# Espressif register map
File version: 1.0
CPU: Xtensa LX6 1, little endian, no MPU, FPU, 3 interrupt priority bits
Registers are 32-bit, access not given, reset 0x0 unless marked. A register's access mark holds for its fields unless they carry their own. Offsets are from the block's base; [hi:lo] are bit positions; {n}, {i} and the like mark numbered series.

## DPORT
Base 0x3FF00000
0x00 DPORT_PRO_BOOT_REMAP_CTRL
  [0] DPORT_PRO_BOOT_REMAP
0x04 DPORT_APP_BOOT_REMAP_CTRL
  [0] DPORT_APP_BOOT_REMAP
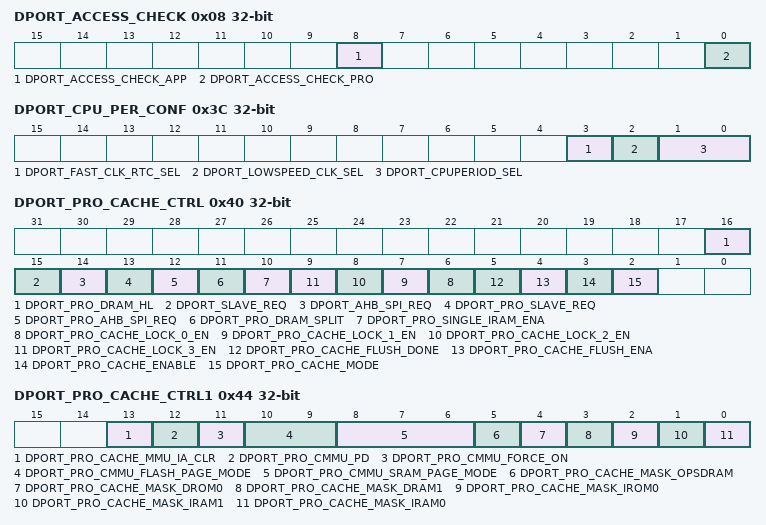
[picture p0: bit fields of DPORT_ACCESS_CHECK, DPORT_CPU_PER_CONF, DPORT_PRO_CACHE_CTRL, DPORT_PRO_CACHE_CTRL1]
0x08 DPORT_ACCESS_CHECK
  [8] DPORT_ACCESS_CHECK_APP, [0] DPORT_ACCESS_CHECK_PRO
0x0C DPORT_PRO_DPORT_APB_MASK0
  [31:0] DPORT_PRODPORT_APB_MASK0
0x10 DPORT_PRO_DPORT_APB_MASK1
  [31:0] DPORT_PRODPORT_APB_MASK1
0x14 DPORT_APP_DPORT_APB_MASK0
  [31:0] DPORT_APPDPORT_APB_MASK0
0x18 DPORT_APP_DPORT_APB_MASK1
  [31:0] DPORT_APPDPORT_APB_MASK1
0x1C DPORT_PERI_CLK_EN
0x20 DPORT_PERI_RST_EN
0x24 DPORT_WIFI_BB_CFG
0x28 DPORT_WIFI_BB_CFG_2
0x2C DPORT_APPCPU_CTRL_A
  [0] DPORT_APPCPU_RESETTING
0x30 DPORT_APPCPU_CTRL_B
  [0] DPORT_APPCPU_CLKGATE_EN
0x34 DPORT_APPCPU_CTRL_C
  [0] DPORT_APPCPU_RUNSTALL
0x38 DPORT_APPCPU_CTRL_D
  [31:0] DPORT_APPCPU_BOOT_ADDR
0x3C DPORT_CPU_PER_CONF
  [3] DPORT_FAST_CLK_RTC_SEL, [2] DPORT_LOWSPEED_CLK_SEL, [1:0] DPORT_CPUPERIOD_SEL
0x40 DPORT_PRO_CACHE_CTRL
  [16] DPORT_PRO_DRAM_HL, [15] DPORT_SLAVE_REQ, [14] DPORT_AHB_SPI_REQ, [13] DPORT_PRO_SLAVE_REQ, [12] DPORT_PRO_AHB_SPI_REQ, [11] DPORT_PRO_DRAM_SPLIT, [10] DPORT_PRO_SINGLE_IRAM_ENA, [n+6] DPORT_PRO_CACHE_LOCK_{n}_EN (n=0..3), [5] DPORT_PRO_CACHE_FLUSH_DONE, [4] DPORT_PRO_CACHE_FLUSH_ENA, [3] DPORT_PRO_CACHE_ENABLE, [2] DPORT_PRO_CACHE_MODE
0x44 DPORT_PRO_CACHE_CTRL1
  [13] DPORT_PRO_CACHE_MMU_IA_CLR, [12] DPORT_PRO_CMMU_PD, [11] DPORT_PRO_CMMU_FORCE_ON, [10:9] DPORT_PRO_CMMU_FLASH_PAGE_MODE, [8:6] DPORT_PRO_CMMU_SRAM_PAGE_MODE, [5] DPORT_PRO_CACHE_MASK_OPSDRAM, [4] DPORT_PRO_CACHE_MASK_DROM0, [3] DPORT_PRO_CACHE_MASK_DRAM1, [2] DPORT_PRO_CACHE_MASK_IROM0, [1] DPORT_PRO_CACHE_MASK_IRAM1, [0] DPORT_PRO_CACHE_MASK_IRAM0
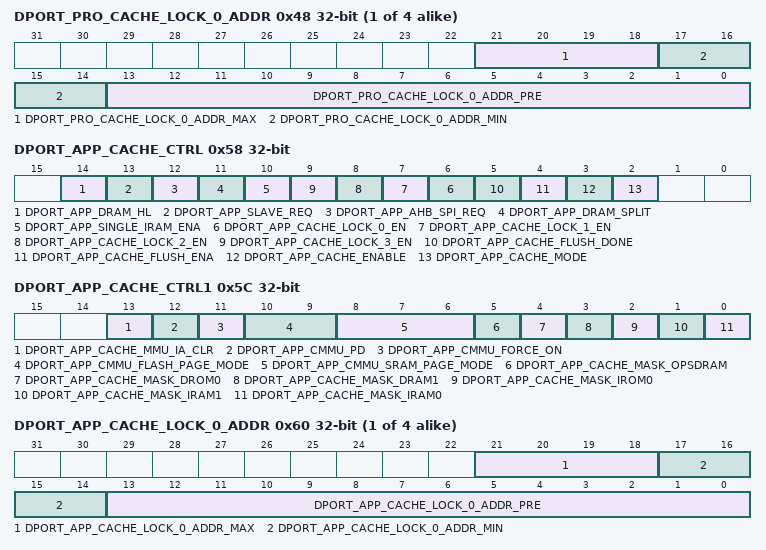
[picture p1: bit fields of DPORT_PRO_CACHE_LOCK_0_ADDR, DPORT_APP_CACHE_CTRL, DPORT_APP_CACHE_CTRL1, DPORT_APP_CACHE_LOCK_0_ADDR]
{0x48+4i} DPORT_PRO_CACHE_LOCK_{i}_ADDR (i=0..3)
  [21:18] DPORT_PRO_CACHE_LOCK_{i}_ADDR_MAX, [17:14] DPORT_PRO_CACHE_LOCK_{i}_ADDR_MIN, [13:0] DPORT_PRO_CACHE_LOCK_{i}_ADDR_PRE
0x58 DPORT_APP_CACHE_CTRL
  [14] DPORT_APP_DRAM_HL, [13] DPORT_APP_SLAVE_REQ, [12] DPORT_APP_AHB_SPI_REQ, [11] DPORT_APP_DRAM_SPLIT, [10] DPORT_APP_SINGLE_IRAM_ENA, [n+6] DPORT_APP_CACHE_LOCK_{n}_EN (n=0..3), [5] DPORT_APP_CACHE_FLUSH_DONE, [4] DPORT_APP_CACHE_FLUSH_ENA, [3] DPORT_APP_CACHE_ENABLE, [2] DPORT_APP_CACHE_MODE
0x5C DPORT_APP_CACHE_CTRL1
  [13] DPORT_APP_CACHE_MMU_IA_CLR, [12] DPORT_APP_CMMU_PD, [11] DPORT_APP_CMMU_FORCE_ON, [10:9] DPORT_APP_CMMU_FLASH_PAGE_MODE, [8:6] DPORT_APP_CMMU_SRAM_PAGE_MODE, [5] DPORT_APP_CACHE_MASK_OPSDRAM, [4] DPORT_APP_CACHE_MASK_DROM0, [3] DPORT_APP_CACHE_MASK_DRAM1, [2] DPORT_APP_CACHE_MASK_IROM0, [1] DPORT_APP_CACHE_MASK_IRAM1, [0] DPORT_APP_CACHE_MASK_IRAM0
{0x60+4i} DPORT_APP_CACHE_LOCK_{i}_ADDR (i=0..3)
  [21:18] DPORT_APP_CACHE_LOCK_{i}_ADDR_MAX, [17:14] DPORT_APP_CACHE_LOCK_{i}_ADDR_MIN, [13:0] DPORT_APP_CACHE_LOCK_{i}_ADDR_PRE
0x70 DPORT_TRACEMEM_MUX_MODE
  [1:0] DPORT_TRACEMEM_MUX_MODE
0x74 DPORT_PRO_TRACEMEM_ENA
  [0] DPORT_PRO_TRACEMEM_ENA
0x78 DPORT_APP_TRACEMEM_ENA
  [0] DPORT_APP_TRACEMEM_ENA
0x7C DPORT_CACHE_MUX_MODE
  [1:0] DPORT_CACHE_MUX_MODE
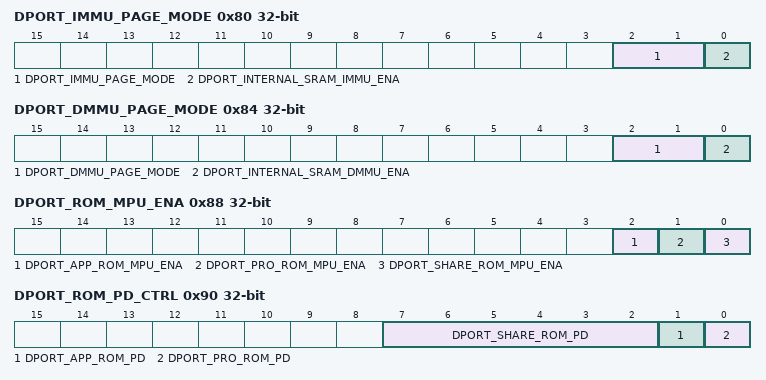
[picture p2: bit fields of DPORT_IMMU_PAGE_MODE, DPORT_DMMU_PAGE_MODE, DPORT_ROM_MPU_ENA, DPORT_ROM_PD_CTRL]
0x80 DPORT_IMMU_PAGE_MODE
  [2:1] DPORT_IMMU_PAGE_MODE, [0] DPORT_INTERNAL_SRAM_IMMU_ENA
0x84 DPORT_DMMU_PAGE_MODE
  [2:1] DPORT_DMMU_PAGE_MODE, [0] DPORT_INTERNAL_SRAM_DMMU_ENA
0x88 DPORT_ROM_MPU_ENA
  [2] DPORT_APP_ROM_MPU_ENA, [1] DPORT_PRO_ROM_MPU_ENA, [0] DPORT_SHARE_ROM_MPU_ENA
0x8C DPORT_MEM_PD_MASK
  [0] DPORT_LSLP_MEM_PD_MASK
0x90 DPORT_ROM_PD_CTRL
  [7:2] DPORT_SHARE_ROM_PD, [1] DPORT_APP_ROM_PD, [0] DPORT_PRO_ROM_PD
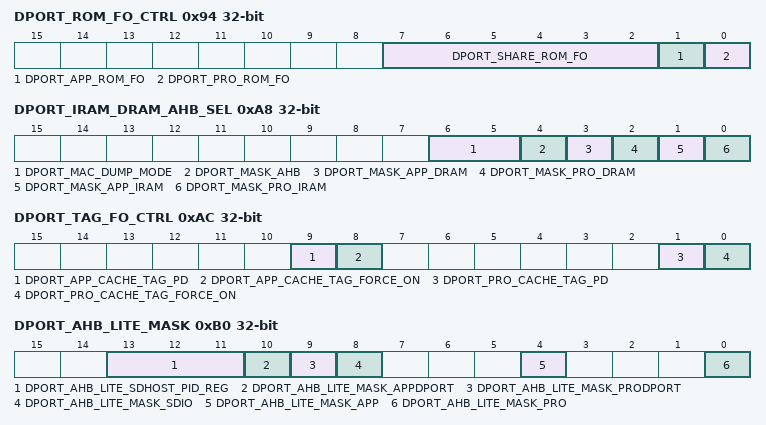
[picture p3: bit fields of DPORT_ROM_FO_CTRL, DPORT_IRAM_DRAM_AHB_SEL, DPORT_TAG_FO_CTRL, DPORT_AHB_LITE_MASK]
0x94 DPORT_ROM_FO_CTRL
  [7:2] DPORT_SHARE_ROM_FO, [1] DPORT_APP_ROM_FO, [0] DPORT_PRO_ROM_FO
0x98 DPORT_SRAM_PD_CTRL_0
  [31:0] DPORT_SRAM_PD_0
0x9C DPORT_SRAM_PD_CTRL_1
  [0] DPORT_SRAM_PD_1
0xA0 DPORT_SRAM_FO_CTRL_0
  [31:0] DPORT_SRAM_FO_0
0xA4 DPORT_SRAM_FO_CTRL_1
  [0] DPORT_SRAM_FO_1
0xA8 DPORT_IRAM_DRAM_AHB_SEL
  [6:5] DPORT_MAC_DUMP_MODE, [4] DPORT_MASK_AHB, [3] DPORT_MASK_APP_DRAM, [2] DPORT_MASK_PRO_DRAM, [1] DPORT_MASK_APP_IRAM, [0] DPORT_MASK_PRO_IRAM
0xAC DPORT_TAG_FO_CTRL
  [9] DPORT_APP_CACHE_TAG_PD, [8] DPORT_APP_CACHE_TAG_FORCE_ON, [1] DPORT_PRO_CACHE_TAG_PD, [0] DPORT_PRO_CACHE_TAG_FORCE_ON
0xB0 DPORT_AHB_LITE_MASK
  [13:11] DPORT_AHB_LITE_SDHOST_PID_REG, [10] DPORT_AHB_LITE_MASK_APPDPORT, [9] DPORT_AHB_LITE_MASK_PRODPORT, [8] DPORT_AHB_LITE_MASK_SDIO, [4] DPORT_AHB_LITE_MASK_APP, [0] DPORT_AHB_LITE_MASK_PRO
0xB4 DPORT_AHB_MPU_TABLE_0
  [31:0] DPORT_AHB_ACCESS_GRANT_0
0xB8 DPORT_AHB_MPU_TABLE_1
  [8:0] DPORT_AHB_ACCESS_GRANT_1
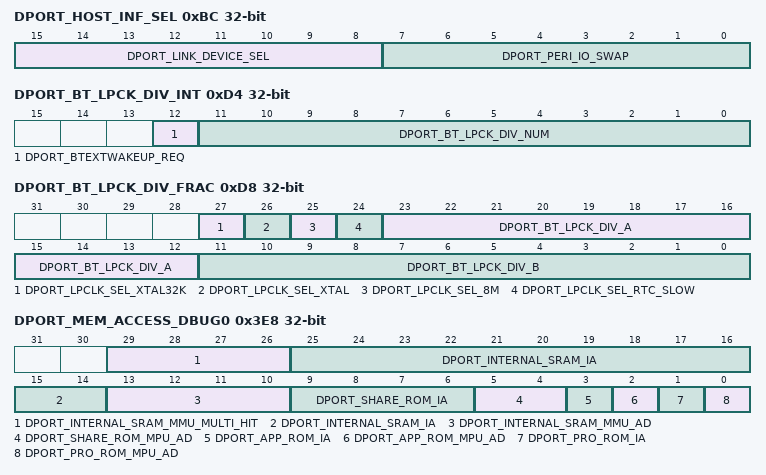
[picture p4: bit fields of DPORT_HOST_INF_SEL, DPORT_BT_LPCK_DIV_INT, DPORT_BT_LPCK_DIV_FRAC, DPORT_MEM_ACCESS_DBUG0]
0xBC DPORT_HOST_INF_SEL
  [15:8] DPORT_LINK_DEVICE_SEL, [7:0] DPORT_PERI_IO_SWAP
0xC0 DPORT_PERIP_CLK_EN
0xC4 DPORT_PERIP_RST_EN
  [12] DPORT_SPI_DECRYPT_ENABLE, [8] DPORT_SPI_ENCRYPT_ENABLE, [4] DPORT_SLAVE_SPI_MASK_APP, [31:0] DPORT_PERIP_RST, [0] DPORT_SLAVE_SPI_MASK_PRO
0xCC DPORT_WIFI_CLK_EN
0xD0 DPORT_CORE_RST_EN
  [31:0] DPORT_CORE_RST
0xD4 DPORT_BT_LPCK_DIV_INT
  [12] DPORT_BTEXTWAKEUP_REQ, [11:0] DPORT_BT_LPCK_DIV_NUM
0xD8 DPORT_BT_LPCK_DIV_FRAC
  [27] DPORT_LPCLK_SEL_XTAL32K, [26] DPORT_LPCLK_SEL_XTAL, [25] DPORT_LPCLK_SEL_8M, [24] DPORT_LPCLK_SEL_RTC_SLOW, [23:12] DPORT_BT_LPCK_DIV_A, [11:0] DPORT_BT_LPCK_DIV_B
{0xDC+4i} DPORT_CPU_INTR_FROM_CPU_{i} (i=0..3)
  [0] DPORT_CPU_INTR_FROM_CPU_{i}
{0xEC+4i} DPORT_PRO_INTR_STATUS_{i} (i=0..2)
{0xF8+4i} DPORT_APP_INTR_STATUS_{i} (i=0..2)
0x104 DPORT_PRO_MAC_INTR_MAP
  [4:0] DPORT_PRO_MAC_INTR_MAP
0x108 DPORT_PRO_MAC_NMI_MAP
  [4:0] DPORT_PRO_MAC_NMI_MAP
0x10C DPORT_PRO_BB_INT_MAP
  [4:0] DPORT_PRO_BB_INT_MAP
0x110 DPORT_PRO_BT_MAC_INT_MAP
  [4:0] DPORT_PRO_BT_MAC_INT_MAP
0x114 DPORT_PRO_BT_BB_INT_MAP
  [4:0] DPORT_PRO_BT_BB_INT_MAP
0x118 DPORT_PRO_BT_BB_NMI_MAP
  [4:0] DPORT_PRO_BT_BB_NMI_MAP
0x11C DPORT_PRO_RWBT_IRQ_MAP
  [4:0] DPORT_PRO_RWBT_IRQ_MAP
0x120 DPORT_PRO_RWBLE_IRQ_MAP
  [4:0] DPORT_PRO_RWBLE_IRQ_MAP
0x124 DPORT_PRO_RWBT_NMI_MAP
  [4:0] DPORT_PRO_RWBT_NMI_MAP
0x128 DPORT_PRO_RWBLE_NMI_MAP
  [4:0] DPORT_PRO_RWBLE_NMI_MAP
0x12C DPORT_PRO_SLC0_INTR_MAP
  [4:0] DPORT_PRO_SLC0_INTR_MAP
0x130 DPORT_PRO_SLC1_INTR_MAP
  [4:0] DPORT_PRO_SLC1_INTR_MAP
0x134 DPORT_PRO_UHCI0_INTR_MAP
  [4:0] DPORT_PRO_UHCI0_INTR_MAP
0x138 DPORT_PRO_UHCI1_INTR_MAP
  [4:0] DPORT_PRO_UHCI1_INTR_MAP
0x13C DPORT_PRO_TG_T0_LEVEL_INT_MAP
  [4:0] DPORT_PRO_TG_T0_LEVEL_INT_MAP
0x140 DPORT_PRO_TG_T1_LEVEL_INT_MAP
  [4:0] DPORT_PRO_TG_T1_LEVEL_INT_MAP
0x144 DPORT_PRO_TG_WDT_LEVEL_INT_MAP
  [4:0] DPORT_PRO_TG_WDT_LEVEL_INT_MAP
0x148 DPORT_PRO_TG_LACT_LEVEL_INT_MAP
  [4:0] DPORT_PRO_TG_LACT_LEVEL_INT_MAP
0x14C DPORT_PRO_TG1_T0_LEVEL_INT_MAP
  [4:0] DPORT_PRO_TG1_T0_LEVEL_INT_MAP
0x150 DPORT_PRO_TG1_T1_LEVEL_INT_MAP
  [4:0] DPORT_PRO_TG1_T1_LEVEL_INT_MAP
0x154 DPORT_PRO_TG1_WDT_LEVEL_INT_MAP
  [4:0] DPORT_PRO_TG1_WDT_LEVEL_INT_MAP
0x158 DPORT_PRO_TG1_LACT_LEVEL_INT_MAP
  [4:0] DPORT_PRO_TG1_LACT_LEVEL_INT_MAP
0x15C DPORT_PRO_GPIO_INTERRUPT_MAP
  [4:0] DPORT_PRO_GPIO_INTERRUPT_PRO_MAP
0x160 DPORT_PRO_GPIO_INTERRUPT_NMI_MAP
  [4:0] DPORT_PRO_GPIO_INTERRUPT_PRO_NMI_MAP
{0x164+4i} DPORT_PRO_CPU_INTR_FROM_CPU_{i}_MAP (i=0..3)
  [4:0] DPORT_PRO_CPU_INTR_FROM_CPU_{i}_MAP
{0x174+4i} DPORT_PRO_SPI_INTR_{i}_MAP (i=0..3)
  [4:0] DPORT_PRO_SPI_INTR_{i}_MAP
0x184 DPORT_PRO_I2S0_INT_MAP
  [4:0] DPORT_PRO_I2S0_INT_MAP
0x188 DPORT_PRO_I2S1_INT_MAP
  [4:0] DPORT_PRO_I2S1_INT_MAP
0x18C DPORT_PRO_UART_INTR_MAP
  [4:0] DPORT_PRO_UART_INTR_MAP
0x190 DPORT_PRO_UART1_INTR_MAP
  [4:0] DPORT_PRO_UART1_INTR_MAP
0x194 DPORT_PRO_UART2_INTR_MAP
  [4:0] DPORT_PRO_UART2_INTR_MAP
0x198 DPORT_PRO_SDIO_HOST_INTERRUPT_MAP
  [4:0] DPORT_PRO_SDIO_HOST_INTERRUPT_MAP
0x19C DPORT_PRO_EMAC_INT_MAP
  [4:0] DPORT_PRO_EMAC_INT_MAP
{0x1A0+4i} DPORT_PRO_PWM{i}_INTR_MAP (i=0..3)
  [4:0] DPORT_PRO_PWM{i}_INTR_MAP
0x1B0 DPORT_PRO_LEDC_INT_MAP
  [4:0] DPORT_PRO_LEDC_INT_MAP
0x1B4 DPORT_PRO_EFUSE_INT_MAP
  [4:0] DPORT_PRO_EFUSE_INT_MAP
0x1B8 DPORT_PRO_CAN_INT_MAP
  [4:0] DPORT_PRO_CAN_INT_MAP
0x1BC DPORT_PRO_RTC_CORE_INTR_MAP
  [4:0] DPORT_PRO_RTC_CORE_INTR_MAP
0x1C0 DPORT_PRO_RMT_INTR_MAP
  [4:0] DPORT_PRO_RMT_INTR_MAP
0x1C4 DPORT_PRO_PCNT_INTR_MAP
  [4:0] DPORT_PRO_PCNT_INTR_MAP
0x1C8 DPORT_PRO_I2C_EXT0_INTR_MAP
  [4:0] DPORT_PRO_I2C_EXT0_INTR_MAP
0x1CC DPORT_PRO_I2C_EXT1_INTR_MAP
  [4:0] DPORT_PRO_I2C_EXT1_INTR_MAP
0x1D0 DPORT_PRO_RSA_INTR_MAP
  [4:0] DPORT_PRO_RSA_INTR_MAP
{0x1D0+4i} DPORT_PRO_SPI{i}_DMA_INT_MAP (i=1..3)
  [4:0] DPORT_PRO_SPI{i}_DMA_INT_MAP
0x1E0 DPORT_PRO_WDG_INT_MAP
  [4:0] DPORT_PRO_WDG_INT_MAP
0x1E4 DPORT_PRO_TIMER_INT1_MAP
  [4:0] DPORT_PRO_TIMER_INT1_MAP
0x1E8 DPORT_PRO_TIMER_INT2_MAP
  [4:0] DPORT_PRO_TIMER_INT2_MAP
0x1EC DPORT_PRO_TG_T0_EDGE_INT_MAP
  [4:0] DPORT_PRO_TG_T0_EDGE_INT_MAP
0x1F0 DPORT_PRO_TG_T1_EDGE_INT_MAP
  [4:0] DPORT_PRO_TG_T1_EDGE_INT_MAP
0x1F4 DPORT_PRO_TG_WDT_EDGE_INT_MAP
  [4:0] DPORT_PRO_TG_WDT_EDGE_INT_MAP
0x1F8 DPORT_PRO_TG_LACT_EDGE_INT_MAP
  [4:0] DPORT_PRO_TG_LACT_EDGE_INT_MAP
0x1FC DPORT_PRO_TG1_T0_EDGE_INT_MAP
  [4:0] DPORT_PRO_TG1_T0_EDGE_INT_MAP
0x200 DPORT_PRO_TG1_T1_EDGE_INT_MAP
  [4:0] DPORT_PRO_TG1_T1_EDGE_INT_MAP
0x204 DPORT_PRO_TG1_WDT_EDGE_INT_MAP
  [4:0] DPORT_PRO_TG1_WDT_EDGE_INT_MAP
0x208 DPORT_PRO_TG1_LACT_EDGE_INT_MAP
  [4:0] DPORT_PRO_TG1_LACT_EDGE_INT_MAP
0x20C DPORT_PRO_MMU_IA_INT_MAP
  [4:0] DPORT_PRO_MMU_IA_INT_MAP
0x210 DPORT_PRO_MPU_IA_INT_MAP
  [4:0] DPORT_PRO_MPU_IA_INT_MAP
0x214 DPORT_PRO_CACHE_IA_INT_MAP
  [4:0] DPORT_PRO_CACHE_IA_INT_MAP
0x218 DPORT_APP_MAC_INTR_MAP
  [4:0] DPORT_APP_MAC_INTR_MAP
0x21C DPORT_APP_MAC_NMI_MAP
  [4:0] DPORT_APP_MAC_NMI_MAP
0x220 DPORT_APP_BB_INT_MAP
  [4:0] DPORT_APP_BB_INT_MAP
0x224 DPORT_APP_BT_MAC_INT_MAP
  [4:0] DPORT_APP_BT_MAC_INT_MAP
0x228 DPORT_APP_BT_BB_INT_MAP
  [4:0] DPORT_APP_BT_BB_INT_MAP
0x22C DPORT_APP_BT_BB_NMI_MAP
  [4:0] DPORT_APP_BT_BB_NMI_MAP
0x230 DPORT_APP_RWBT_IRQ_MAP
  [4:0] DPORT_APP_RWBT_IRQ_MAP
0x234 DPORT_APP_RWBLE_IRQ_MAP
  [4:0] DPORT_APP_RWBLE_IRQ_MAP
0x238 DPORT_APP_RWBT_NMI_MAP
  [4:0] DPORT_APP_RWBT_NMI_MAP
0x23C DPORT_APP_RWBLE_NMI_MAP
  [4:0] DPORT_APP_RWBLE_NMI_MAP
0x240 DPORT_APP_SLC0_INTR_MAP
  [4:0] DPORT_APP_SLC0_INTR_MAP
0x244 DPORT_APP_SLC1_INTR_MAP
  [4:0] DPORT_APP_SLC1_INTR_MAP
0x248 DPORT_APP_UHCI0_INTR_MAP
  [4:0] DPORT_APP_UHCI0_INTR_MAP
0x24C DPORT_APP_UHCI1_INTR_MAP
  [4:0] DPORT_APP_UHCI1_INTR_MAP
0x250 DPORT_APP_TG_T0_LEVEL_INT_MAP
  [4:0] DPORT_APP_TG_T0_LEVEL_INT_MAP
0x254 DPORT_APP_TG_T1_LEVEL_INT_MAP
  [4:0] DPORT_APP_TG_T1_LEVEL_INT_MAP
0x258 DPORT_APP_TG_WDT_LEVEL_INT_MAP
  [4:0] DPORT_APP_TG_WDT_LEVEL_INT_MAP
0x25C DPORT_APP_TG_LACT_LEVEL_INT_MAP
  [4:0] DPORT_APP_TG_LACT_LEVEL_INT_MAP
0x260 DPORT_APP_TG1_T0_LEVEL_INT_MAP
  [4:0] DPORT_APP_TG1_T0_LEVEL_INT_MAP
0x264 DPORT_APP_TG1_T1_LEVEL_INT_MAP
  [4:0] DPORT_APP_TG1_T1_LEVEL_INT_MAP
0x268 DPORT_APP_TG1_WDT_LEVEL_INT_MAP
  [4:0] DPORT_APP_TG1_WDT_LEVEL_INT_MAP
0x26C DPORT_APP_TG1_LACT_LEVEL_INT_MAP
  [4:0] DPORT_APP_TG1_LACT_LEVEL_INT_MAP
0x270 DPORT_APP_GPIO_INTERRUPT_MAP
  [4:0] DPORT_APP_GPIO_INTERRUPT_APP_MAP
0x274 DPORT_APP_GPIO_INTERRUPT_NMI_MAP
  [4:0] DPORT_APP_GPIO_INTERRUPT_APP_NMI_MAP
{0x278+4i} DPORT_APP_CPU_INTR_FROM_CPU_{i}_MAP (i=0..3)
  [4:0] DPORT_APP_CPU_INTR_FROM_CPU_{i}_MAP
{0x288+4i} DPORT_APP_SPI_INTR_{i}_MAP (i=0..3)
  [4:0] DPORT_APP_SPI_INTR_{i}_MAP
0x298 DPORT_APP_I2S0_INT_MAP
  [4:0] DPORT_APP_I2S0_INT_MAP
0x29C DPORT_APP_I2S1_INT_MAP
  [4:0] DPORT_APP_I2S1_INT_MAP
0x2A0 DPORT_APP_UART_INTR_MAP
  [4:0] DPORT_APP_UART_INTR_MAP
0x2A4 DPORT_APP_UART1_INTR_MAP
  [4:0] DPORT_APP_UART1_INTR_MAP
0x2A8 DPORT_APP_UART2_INTR_MAP
  [4:0] DPORT_APP_UART2_INTR_MAP
0x2AC DPORT_APP_SDIO_HOST_INTERRUPT_MAP
  [4:0] DPORT_APP_SDIO_HOST_INTERRUPT_MAP
0x2B0 DPORT_APP_EMAC_INT_MAP
  [4:0] DPORT_APP_EMAC_INT_MAP
{0x2B4+4i} DPORT_APP_PWM{i}_INTR_MAP (i=0..3)
  [4:0] DPORT_APP_PWM{i}_INTR_MAP
0x2C4 DPORT_APP_LEDC_INT_MAP
  [4:0] DPORT_APP_LEDC_INT_MAP
0x2C8 DPORT_APP_EFUSE_INT_MAP
  [4:0] DPORT_APP_EFUSE_INT_MAP
0x2CC DPORT_APP_CAN_INT_MAP
  [4:0] DPORT_APP_CAN_INT_MAP
0x2D0 DPORT_APP_RTC_CORE_INTR_MAP
  [4:0] DPORT_APP_RTC_CORE_INTR_MAP
0x2D4 DPORT_APP_RMT_INTR_MAP
  [4:0] DPORT_APP_RMT_INTR_MAP
0x2D8 DPORT_APP_PCNT_INTR_MAP
  [4:0] DPORT_APP_PCNT_INTR_MAP
0x2DC DPORT_APP_I2C_EXT0_INTR_MAP
  [4:0] DPORT_APP_I2C_EXT0_INTR_MAP
0x2E0 DPORT_APP_I2C_EXT1_INTR_MAP
  [4:0] DPORT_APP_I2C_EXT1_INTR_MAP
0x2E4 DPORT_APP_RSA_INTR_MAP
  [4:0] DPORT_APP_RSA_INTR_MAP
{0x2E4+4i} DPORT_APP_SPI{i}_DMA_INT_MAP (i=1..3)
  [4:0] DPORT_APP_SPI{i}_DMA_INT_MAP
0x2F4 DPORT_APP_WDG_INT_MAP
  [4:0] DPORT_APP_WDG_INT_MAP
0x2F8 DPORT_APP_TIMER_INT1_MAP
  [4:0] DPORT_APP_TIMER_INT1_MAP
0x2FC DPORT_APP_TIMER_INT2_MAP
  [4:0] DPORT_APP_TIMER_INT2_MAP
0x300 DPORT_APP_TG_T0_EDGE_INT_MAP
  [4:0] DPORT_APP_TG_T0_EDGE_INT_MAP
0x304 DPORT_APP_TG_T1_EDGE_INT_MAP
  [4:0] DPORT_APP_TG_T1_EDGE_INT_MAP
0x308 DPORT_APP_TG_WDT_EDGE_INT_MAP
  [4:0] DPORT_APP_TG_WDT_EDGE_INT_MAP
0x30C DPORT_APP_TG_LACT_EDGE_INT_MAP
  [4:0] DPORT_APP_TG_LACT_EDGE_INT_MAP
0x310 DPORT_APP_TG1_T0_EDGE_INT_MAP
  [4:0] DPORT_APP_TG1_T0_EDGE_INT_MAP
0x314 DPORT_APP_TG1_T1_EDGE_INT_MAP
  [4:0] DPORT_APP_TG1_T1_EDGE_INT_MAP
0x318 DPORT_APP_TG1_WDT_EDGE_INT_MAP
  [4:0] DPORT_APP_TG1_WDT_EDGE_INT_MAP
0x31C DPORT_APP_TG1_LACT_EDGE_INT_MAP
  [4:0] DPORT_APP_TG1_LACT_EDGE_INT_MAP
0x320 DPORT_APP_MMU_IA_INT_MAP
  [4:0] DPORT_APP_MMU_IA_INT_MAP
0x324 DPORT_APP_MPU_IA_INT_MAP
  [4:0] DPORT_APP_MPU_IA_INT_MAP
0x328 DPORT_APP_CACHE_IA_INT_MAP
  [4:0] DPORT_APP_CACHE_IA_INT_MAP
0x32C DPORT_AHBLITE_MPU_TABLE_UART
  [5:0] DPORT_UART_ACCESS_GRANT_CONFIG
0x330 DPORT_AHBLITE_MPU_TABLE_SPI1
  [5:0] DPORT_SPI1_ACCESS_GRANT_CONFIG
0x334 DPORT_AHBLITE_MPU_TABLE_SPI0
  [5:0] DPORT_SPI0_ACCESS_GRANT_CONFIG
0x338 DPORT_AHBLITE_MPU_TABLE_GPIO
  [5:0] DPORT_GPIO_ACCESS_GRANT_CONFIG
0x33C DPORT_AHBLITE_MPU_TABLE_FE2
  [5:0] DPORT_FE2_ACCESS_GRANT_CONFIG
0x340 DPORT_AHBLITE_MPU_TABLE_FE
  [5:0] DPORT_FE_ACCESS_GRANT_CONFIG
0x344 DPORT_AHBLITE_MPU_TABLE_TIMER
  [5:0] DPORT_TIMER_ACCESS_GRANT_CONFIG
0x348 DPORT_AHBLITE_MPU_TABLE_RTC
  [5:0] DPORT_RTC_ACCESS_GRANT_CONFIG
0x34C DPORT_AHBLITE_MPU_TABLE_IO_MUX
  [5:0] DPORT_IOMUX_ACCESS_GRANT_CONFIG
0x350 DPORT_AHBLITE_MPU_TABLE_WDG
  [5:0] DPORT_WDG_ACCESS_GRANT_CONFIG
0x354 DPORT_AHBLITE_MPU_TABLE_HINF
  [5:0] DPORT_HINF_ACCESS_GRANT_CONFIG
0x358 DPORT_AHBLITE_MPU_TABLE_UHCI1
  [5:0] DPORT_UHCI1_ACCESS_GRANT_CONFIG
0x35C DPORT_AHBLITE_MPU_TABLE_MISC
  [5:0] DPORT_MISC_ACCESS_GRANT_CONFIG
0x360 DPORT_AHBLITE_MPU_TABLE_I2C
  [5:0] DPORT_I2C_ACCESS_GRANT_CONFIG
0x364 DPORT_AHBLITE_MPU_TABLE_I2S0
  [5:0] DPORT_I2S0_ACCESS_GRANT_CONFIG
0x368 DPORT_AHBLITE_MPU_TABLE_UART1
  [5:0] DPORT_UART1_ACCESS_GRANT_CONFIG
0x36C DPORT_AHBLITE_MPU_TABLE_BT
  [5:0] DPORT_BT_ACCESS_GRANT_CONFIG
0x370 DPORT_AHBLITE_MPU_TABLE_BT_BUFFER
  [5:0] DPORT_BTBUFFER_ACCESS_GRANT_CONFIG
0x374 DPORT_AHBLITE_MPU_TABLE_I2C_EXT0
  [5:0] DPORT_I2CEXT0_ACCESS_GRANT_CONFIG
0x378 DPORT_AHBLITE_MPU_TABLE_UHCI0
  [5:0] DPORT_UHCI0_ACCESS_GRANT_CONFIG
0x37C DPORT_AHBLITE_MPU_TABLE_SLCHOST
  [5:0] DPORT_SLCHOST_ACCESS_GRANT_CONFIG
0x380 DPORT_AHBLITE_MPU_TABLE_RMT
  [5:0] DPORT_RMT_ACCESS_GRANT_CONFIG
0x384 DPORT_AHBLITE_MPU_TABLE_PCNT
  [5:0] DPORT_PCNT_ACCESS_GRANT_CONFIG
0x388 DPORT_AHBLITE_MPU_TABLE_SLC
  [5:0] DPORT_SLC_ACCESS_GRANT_CONFIG
0x38C DPORT_AHBLITE_MPU_TABLE_LEDC
  [5:0] DPORT_LEDC_ACCESS_GRANT_CONFIG
0x390 DPORT_AHBLITE_MPU_TABLE_EFUSE
  [5:0] DPORT_EFUSE_ACCESS_GRANT_CONFIG
0x394 DPORT_AHBLITE_MPU_TABLE_SPI_ENCRYPT
  [5:0] DPORT_SPI_ENCRYPY_ACCESS_GRANT_CONFIG
0x398 DPORT_AHBLITE_MPU_TABLE_BB
  [5:0] DPORT_BB_ACCESS_GRANT_CONFIG
0x39C DPORT_AHBLITE_MPU_TABLE_PWM0
  [5:0] DPORT_PWM0_ACCESS_GRANT_CONFIG
0x3A0 DPORT_AHBLITE_MPU_TABLE_TIMERGROUP
  [5:0] DPORT_TIMERGROUP_ACCESS_GRANT_CONFIG
0x3A4 DPORT_AHBLITE_MPU_TABLE_TIMERGROUP1
  [5:0] DPORT_TIMERGROUP1_ACCESS_GRANT_CONFIG
0x3A8 DPORT_AHBLITE_MPU_TABLE_SPI2
  [5:0] DPORT_SPI2_ACCESS_GRANT_CONFIG
0x3AC DPORT_AHBLITE_MPU_TABLE_SPI3
  [5:0] DPORT_SPI3_ACCESS_GRANT_CONFIG
0x3B0 DPORT_AHBLITE_MPU_TABLE_APB_CTRL
  [5:0] DPORT_APBCTRL_ACCESS_GRANT_CONFIG
0x3B4 DPORT_AHBLITE_MPU_TABLE_I2C_EXT1
  [5:0] DPORT_I2CEXT1_ACCESS_GRANT_CONFIG
0x3B8 DPORT_AHBLITE_MPU_TABLE_SDIO_HOST
  [5:0] DPORT_SDIOHOST_ACCESS_GRANT_CONFIG
0x3BC DPORT_AHBLITE_MPU_TABLE_EMAC
  [5:0] DPORT_EMAC_ACCESS_GRANT_CONFIG
0x3C0 DPORT_AHBLITE_MPU_TABLE_CAN
  [5:0] DPORT_CAN_ACCESS_GRANT_CONFIG
0x3C4 DPORT_AHBLITE_MPU_TABLE_PWM1
  [5:0] DPORT_PWM1_ACCESS_GRANT_CONFIG
0x3C8 DPORT_AHBLITE_MPU_TABLE_I2S1
  [5:0] DPORT_I2S1_ACCESS_GRANT_CONFIG
0x3CC DPORT_AHBLITE_MPU_TABLE_UART2
  [5:0] DPORT_UART2_ACCESS_GRANT_CONFIG
0x3D0 DPORT_AHBLITE_MPU_TABLE_PWM2
  [5:0] DPORT_PWM2_ACCESS_GRANT_CONFIG
0x3D4 DPORT_AHBLITE_MPU_TABLE_PWM3
  [5:0] DPORT_PWM3_ACCESS_GRANT_CONFIG
0x3D8 DPORT_AHBLITE_MPU_TABLE_RWBT
  [5:0] DPORT_RWBT_ACCESS_GRANT_CONFIG
0x3DC DPORT_AHBLITE_MPU_TABLE_BTMAC
  [5:0] DPORT_BTMAC_ACCESS_GRANT_CONFIG
0x3E0 DPORT_AHBLITE_MPU_TABLE_WIFIMAC
  [5:0] DPORT_WIFIMAC_ACCESS_GRANT_CONFIG
0x3E4 DPORT_AHBLITE_MPU_TABLE_PWR
  [5:0] DPORT_PWR_ACCESS_GRANT_CONFIG
0x3E8 DPORT_MEM_ACCESS_DBUG0
  [29:26] DPORT_INTERNAL_SRAM_MMU_MULTI_HIT, [25:14] DPORT_INTERNAL_SRAM_IA, [13:10] DPORT_INTERNAL_SRAM_MMU_AD, [9:6] DPORT_SHARE_ROM_IA, [5:4] DPORT_SHARE_ROM_MPU_AD, [3] DPORT_APP_ROM_IA, [2] DPORT_APP_ROM_MPU_AD, [1] DPORT_PRO_ROM_IA, [0] DPORT_PRO_ROM_MPU_AD
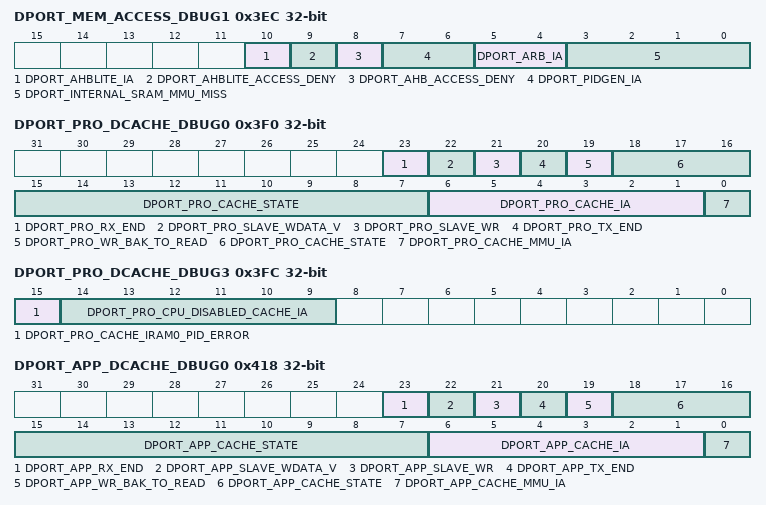
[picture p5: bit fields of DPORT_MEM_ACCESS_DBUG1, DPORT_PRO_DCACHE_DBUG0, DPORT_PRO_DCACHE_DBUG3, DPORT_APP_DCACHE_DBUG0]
0x3EC DPORT_MEM_ACCESS_DBUG1
  [10] DPORT_AHBLITE_IA, [9] DPORT_AHBLITE_ACCESS_DENY, [8] DPORT_AHB_ACCESS_DENY, [7:6] DPORT_PIDGEN_IA, [5:4] DPORT_ARB_IA, [3:0] DPORT_INTERNAL_SRAM_MMU_MISS
0x3F0 DPORT_PRO_DCACHE_DBUG0
  [23] DPORT_PRO_RX_END, [22] DPORT_PRO_SLAVE_WDATA_V, [21] DPORT_PRO_SLAVE_WR, [20] DPORT_PRO_TX_END, [19] DPORT_PRO_WR_BAK_TO_READ, [18:7] DPORT_PRO_CACHE_STATE, [6:1] DPORT_PRO_CACHE_IA, [0] DPORT_PRO_CACHE_MMU_IA
0x3F4 DPORT_PRO_DCACHE_DBUG1
  [31:0] DPORT_PRO_CTAG_RAM_RDATA
0x3F8 DPORT_PRO_DCACHE_DBUG2
  [26:0] DPORT_PRO_CACHE_VADDR
0x3FC DPORT_PRO_DCACHE_DBUG3
  [15] DPORT_PRO_CACHE_IRAM0_PID_ERROR, [14:9] DPORT_PRO_CPU_DISABLED_CACHE_IA
0x400 DPORT_PRO_DCACHE_DBUG4
  [19:0] DPORT_PRO_DRAM1ADDR0_IA
0x404 DPORT_PRO_DCACHE_DBUG5
  [19:0] DPORT_PRO_DROM0ADDR0_IA
0x408 DPORT_PRO_DCACHE_DBUG6
  [19:0] DPORT_PRO_IRAM0ADDR_IA
0x40C DPORT_PRO_DCACHE_DBUG7
  [19:0] DPORT_PRO_IRAM1ADDR_IA
0x410 DPORT_PRO_DCACHE_DBUG8
  [19:0] DPORT_PRO_IROM0ADDR_IA
0x414 DPORT_PRO_DCACHE_DBUG9
  [19:0] DPORT_PRO_OPSDRAMADDR_IA
0x418 DPORT_APP_DCACHE_DBUG0
  [23] DPORT_APP_RX_END, [22] DPORT_APP_SLAVE_WDATA_V, [21] DPORT_APP_SLAVE_WR, [20] DPORT_APP_TX_END, [19] DPORT_APP_WR_BAK_TO_READ, [18:7] DPORT_APP_CACHE_STATE, [6:1] DPORT_APP_CACHE_IA, [0] DPORT_APP_CACHE_MMU_IA
0x41C DPORT_APP_DCACHE_DBUG1
  [31:0] DPORT_APP_CTAG_RAM_RDATA
0x420 DPORT_APP_DCACHE_DBUG2
  [26:0] DPORT_APP_CACHE_VADDR
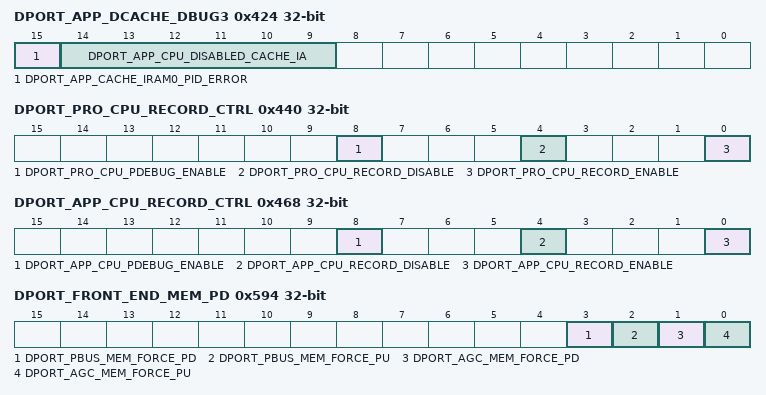
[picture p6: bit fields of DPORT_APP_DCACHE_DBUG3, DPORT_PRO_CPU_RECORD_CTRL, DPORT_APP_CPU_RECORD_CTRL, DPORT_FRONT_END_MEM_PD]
0x424 DPORT_APP_DCACHE_DBUG3
  [15] DPORT_APP_CACHE_IRAM0_PID_ERROR, [14:9] DPORT_APP_CPU_DISABLED_CACHE_IA
0x428 DPORT_APP_DCACHE_DBUG4
  [19:0] DPORT_APP_DRAM1ADDR0_IA
0x42C DPORT_APP_DCACHE_DBUG5
  [19:0] DPORT_APP_DROM0ADDR0_IA
0x430 DPORT_APP_DCACHE_DBUG6
  [19:0] DPORT_APP_IRAM0ADDR_IA
0x434 DPORT_APP_DCACHE_DBUG7
  [19:0] DPORT_APP_IRAM1ADDR_IA
0x438 DPORT_APP_DCACHE_DBUG8
  [19:0] DPORT_APP_IROM0ADDR_IA
0x43C DPORT_APP_DCACHE_DBUG9
  [19:0] DPORT_APP_OPSDRAMADDR_IA
0x440 DPORT_PRO_CPU_RECORD_CTRL
  [8] DPORT_PRO_CPU_PDEBUG_ENABLE, [4] DPORT_PRO_CPU_RECORD_DISABLE, [0] DPORT_PRO_CPU_RECORD_ENABLE
0x444 DPORT_PRO_CPU_RECORD_STATUS
  [0] DPORT_PRO_CPU_RECORDING
0x448 DPORT_PRO_CPU_RECORD_PID
  [2:0] DPORT_RECORD_PRO_PID
0x44C DPORT_PRO_CPU_RECORD_PDEBUGINST
  [31:0] DPORT_RECORD_PRO_PDEBUGINST
0x450 DPORT_PRO_CPU_RECORD_PDEBUGSTATUS
  [7:0] DPORT_RECORD_PRO_PDEBUGSTATUS
0x454 DPORT_PRO_CPU_RECORD_PDEBUGDATA
  [31:0] DPORT_RECORD_PRO_PDEBUGDATA
0x458 DPORT_PRO_CPU_RECORD_PDEBUGPC
  [31:0] DPORT_RECORD_PRO_PDEBUGPC
0x45C DPORT_PRO_CPU_RECORD_PDEBUGLS0STAT
  [31:0] DPORT_RECORD_PRO_PDEBUGLS0STAT
0x460 DPORT_PRO_CPU_RECORD_PDEBUGLS0ADDR
  [31:0] DPORT_RECORD_PRO_PDEBUGLS0ADDR
0x464 DPORT_PRO_CPU_RECORD_PDEBUGLS0DATA
  [31:0] DPORT_RECORD_PRO_PDEBUGLS0DATA
0x468 DPORT_APP_CPU_RECORD_CTRL
  [8] DPORT_APP_CPU_PDEBUG_ENABLE, [4] DPORT_APP_CPU_RECORD_DISABLE, [0] DPORT_APP_CPU_RECORD_ENABLE
0x46C DPORT_APP_CPU_RECORD_STATUS
  [0] DPORT_APP_CPU_RECORDING
0x470 DPORT_APP_CPU_RECORD_PID
  [2:0] DPORT_RECORD_APP_PID
0x474 DPORT_APP_CPU_RECORD_PDEBUGINST
  [31:0] DPORT_RECORD_APP_PDEBUGINST
0x478 DPORT_APP_CPU_RECORD_PDEBUGSTATUS
  [7:0] DPORT_RECORD_APP_PDEBUGSTATUS
0x47C DPORT_APP_CPU_RECORD_PDEBUGDATA
  [31:0] DPORT_RECORD_APP_PDEBUGDATA
0x480 DPORT_APP_CPU_RECORD_PDEBUGPC
  [31:0] DPORT_RECORD_APP_PDEBUGPC
0x484 DPORT_APP_CPU_RECORD_PDEBUGLS0STAT
  [31:0] DPORT_RECORD_APP_PDEBUGLS0STAT
0x488 DPORT_APP_CPU_RECORD_PDEBUGLS0ADDR
  [31:0] DPORT_RECORD_APP_PDEBUGLS0ADDR
0x48C DPORT_APP_CPU_RECORD_PDEBUGLS0DATA
  [31:0] DPORT_RECORD_APP_PDEBUGLS0DATA
0x490 DPORT_RSA_PD_CTRL
  [0] DPORT_RSA_PD
{0x494+4i} DPORT_ROM_MPU_TABLE{i} (i=0..3)
  [1:0] DPORT_ROM_MPU_TABLE{i}
{0x4A4+4i} DPORT_SHROM_MPU_TABLE{i} (i=0..23)
  [1:0] DPORT_SHROM_MPU_TABLE{i}
{0x504+4i} DPORT_IMMU_TABLE{i} (i=0..15)
  [6:0] DPORT_IMMU_TABLE{i}
{0x544+4i} DPORT_DMMU_TABLE{i} (i=0..15)
  [6:0] DPORT_DMMU_TABLE{i}
0x584 DPORT_PRO_INTRUSION_CTRL
  [0] DPORT_PRO_INTRUSION_RECORD_RESET_N
0x588 DPORT_PRO_INTRUSION_STATUS
  [3:0] DPORT_PRO_INTRUSION_RECORD
0x58C DPORT_APP_INTRUSION_CTRL
  [0] DPORT_APP_INTRUSION_RECORD_RESET_N
0x590 DPORT_APP_INTRUSION_STATUS
  [3:0] DPORT_APP_INTRUSION_RECORD
0x594 DPORT_FRONT_END_MEM_PD
  [3] DPORT_PBUS_MEM_FORCE_PD, [2] DPORT_PBUS_MEM_FORCE_PU, [1] DPORT_AGC_MEM_FORCE_PD, [0] DPORT_AGC_MEM_FORCE_PU
0x598 DPORT_MMU_IA_INT_EN
  [23:0] DPORT_MMU_IA_INT_EN
0x59C DPORT_MPU_IA_INT_EN
  [16:0] DPORT_MPU_IA_INT_EN
0x5A0 DPORT_CACHE_IA_INT_EN
  [19] DPORT_CACHE_IA_INT_PRO_OPPOSITE, [18] DPORT_CACHE_IA_INT_PRO_DRAM1, [17] DPORT_CACHE_IA_INT_PRO_IROM0, [16] DPORT_CACHE_IA_INT_PRO_IRAM1, [15] DPORT_CACHE_IA_INT_PRO_IRAM0, [14] DPORT_CACHE_IA_INT_PRO_DROM0, [5] DPORT_CACHE_IA_INT_APP_OPPOSITE, [3] DPORT_CACHE_IA_INT_APP_IROM0, [2] DPORT_CACHE_IA_INT_APP_IRAM1, [1] DPORT_CACHE_IA_INT_APP_IRAM0, [27:0] DPORT_CACHE_IA_INT_EN, [0] DPORT_CACHE_IA_INT_APP_DROM0
0x5A4 DPORT_SECURE_BOOT_CTRL
  [0] DPORT_SW_BOOTLOADER_SEL
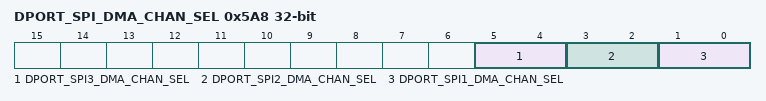
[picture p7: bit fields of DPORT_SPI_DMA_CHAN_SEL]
0x5A8 DPORT_SPI_DMA_CHAN_SEL
  [5:4] DPORT_SPI3_DMA_CHAN_SEL, [3:2] DPORT_SPI2_DMA_CHAN_SEL, [1:0] DPORT_SPI1_DMA_CHAN_SEL
0x5AC DPORT_PRO_VECBASE_CTRL
  [1:0] DPORT_PRO_OUT_VECBASE_SEL
0x5B0 DPORT_PRO_VECBASE_SET
  [21:0] DPORT_PRO_OUT_VECBASE_REG
0x5B4 DPORT_APP_VECBASE_CTRL
  [1:0] DPORT_APP_OUT_VECBASE_SEL
0x5B8 DPORT_APP_VECBASE_SET
  [21:0] DPORT_APP_OUT_VECBASE_REG
0xFFC DPORT_DATE
  [27:0] DPORT_DATE
